# RX64M_EXDMAC0_Pilot register map
File version: 1.0
RX64M_EXDMAC0_Pilot peripheral registers generated from iodefine.h (pilot).
Registers are 8-bit, read-write, reset 0x0 unless marked. A register's access mark holds for its fields unless they carry their own. Offsets are from the block's base; lines under a group give offsets from that group; [hi:lo] are bit positions; {n}, {i} and the like mark numbered series; 'fields as' and 'values as' point back to an identical list; <NAME> marks a mode.

## Memory map
0x00082800 EXDMAC0 size 0x23

## EXDMAC0
Base 0x00082800
0x00 EDMSAR 32-bit
0x04 EDMDAR 32-bit
0x08 EDMCRA 32-bit
0x0C EDMCRB 16-bit
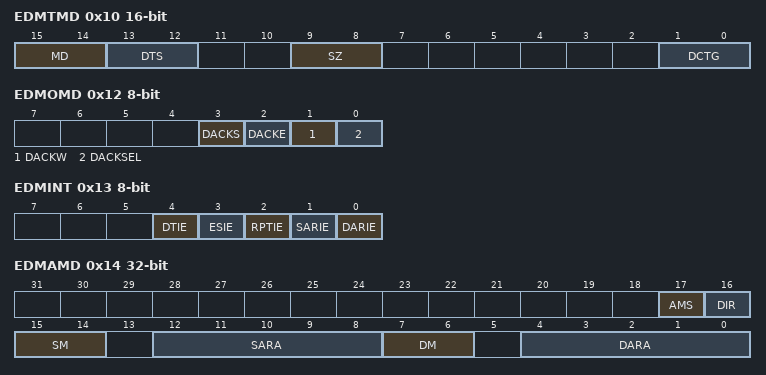
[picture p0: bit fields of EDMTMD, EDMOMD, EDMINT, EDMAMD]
0x10 EDMTMD 16-bit
  [15:14] MD, [13:12] DTS, [9:8] SZ, [1:0] DCTG
0x12 EDMOMD
  [3] DACKS, [2] DACKE, [1] DACKW, [0] DACKSEL
0x13 EDMINT
  [4] DTIE, [3] ESIE, [2] RPTIE, [1] SARIE, [0] DARIE
0x14 EDMAMD 32-bit
  [17] AMS, [16] DIR, [15:14] SM, [12:8] SARA, [7:6] DM, [4:0] DARA
0x18 EDMOFR 32-bit
0x1C EDMCNT
  [0] DTE
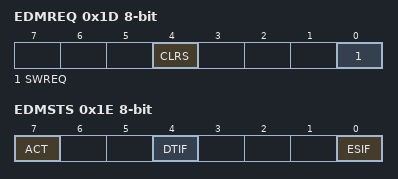
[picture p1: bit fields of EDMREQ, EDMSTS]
0x1D EDMREQ
  [4] CLRS, [0] SWREQ
0x1E EDMSTS
  [7] ACT, [4] DTIF, [0] ESIF
0x20 EDMRMD
  [1:0] DREQS
0x21 EDMERF
  [0] EREQ
0x22 EDMPRF
  [0] PREQ
